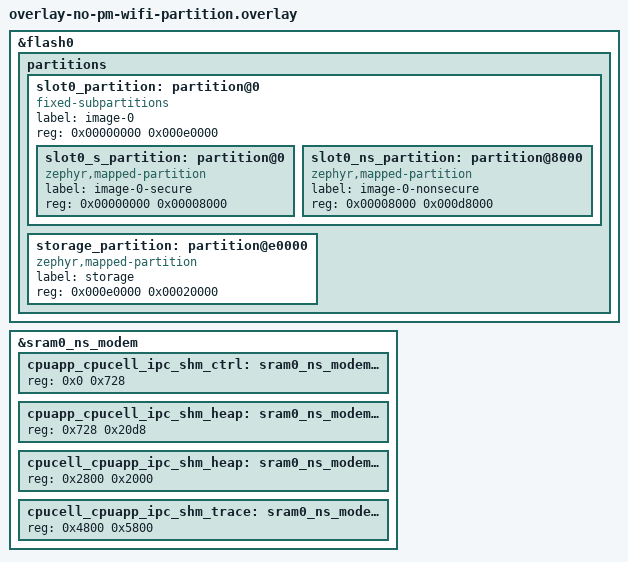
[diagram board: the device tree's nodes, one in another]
/*
 * Copyright (c) 2026 Nordic Semiconductor ASA
 *
 * SPDX-License-Identifier: LicenseRef-Nordic-5-Clause
 */

/*
 * DTS overlay for no-Partition-Manager Wi-Fi variants.
 *
 * Provides a larger static slot0 layout for Wi-Fi builds and defines
 * modem shared-memory labels required when PARTITION_MANAGER=n.
 *
 * Flash layout:
 * - slot0_partition: 0x00000000..0x000e0000
 *   - slot0_s_partition:  0x00000000..0x00008000
 *   - slot0_ns_partition: 0x00008000..0x000e0000
 * - storage_partition: 0x000e0000..0x00100000
 */

/delete-node/ &boot_partition;
/delete-node/ &slot0_partition;
/delete-node/ &slot1_partition;
/delete-node/ &tfm_ps_partition;
/delete-node/ &tfm_its_partition;
/delete-node/ &tfm_otp_partition;
/delete-node/ &storage_partition;

&flash0 {
	partitions {
		ranges;
		#address-cells = <1>;
		#size-cells = <1>;

		slot0_partition: partition@0 {
			compatible = "fixed-subpartitions";
			label = "image-0";
			reg = <0x00000000 0x000e0000>;
			ranges = <0x0 0x00000000 0x000e0000>;
			#address-cells = <1>;
			#size-cells = <1>;

			slot0_s_partition: partition@0 {
				compatible = "zephyr,mapped-partition";
				label = "image-0-secure";
				reg = <0x00000000 0x00008000>;
			};

			slot0_ns_partition: partition@8000 {
				compatible = "zephyr,mapped-partition";
				label = "image-0-nonsecure";
				reg = <0x00008000 0x000d8000>;
			};
		};

		storage_partition: partition@e0000 {
			compatible = "zephyr,mapped-partition";
			label = "storage";
			reg = <0x000e0000 0x00020000>;
		};
	};
};

&sram0_ns_modem {
	#address-cells = <1>;
	#size-cells = <1>;
	ranges = <0x0 0x0 0xa000>;

	cpuapp_cpucell_ipc_shm_ctrl: sram0_ns_modem@0 {
		reg = <0x0 0x728>;
	};

	cpuapp_cpucell_ipc_shm_heap: sram0_ns_modem@728 {
		reg = <0x728 0x20d8>;
	};

	cpucell_cpuapp_ipc_shm_heap: sram0_ns_modem@2800 {
		reg = <0x2800 0x2000>;
	};

	cpucell_cpuapp_ipc_shm_trace: sram0_ns_modem@4800 {
		reg = <0x4800 0x5800>;
	};
};
